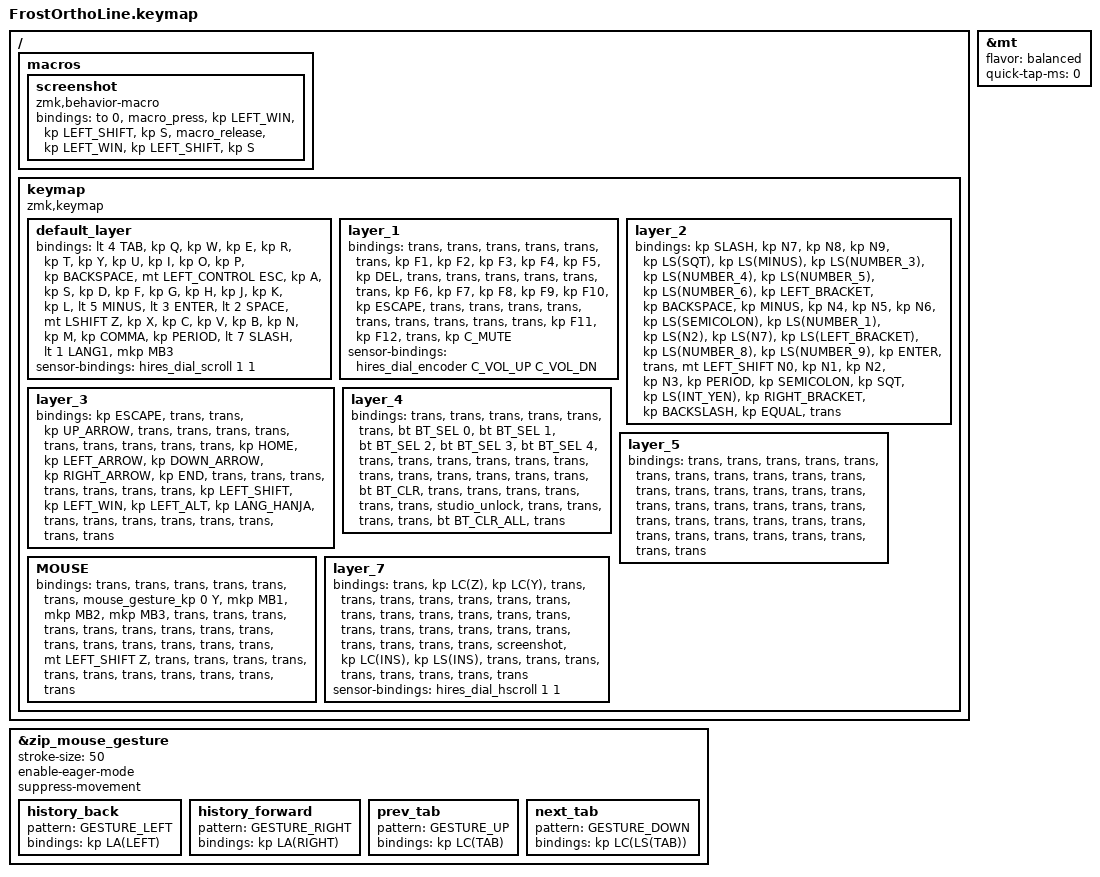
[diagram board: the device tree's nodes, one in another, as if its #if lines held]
#include <input/processors.dtsi>
#include <behaviors.dtsi>
#include <dt-bindings/zmk/bt.h>
#include <dt-bindings/zmk/keys.h>
#include <dt-bindings/zmk/pointing.h>
#include <mouse-gesture.dtsi>

#define MOUSE 6

&mt {
    flavor = "balanced";
    quick-tap-ms = <0>;
};

// マウスジェスチャー（AMLのYキーを長押ししながらセンサー1を動かす）
&zip_mouse_gesture {
    stroke-size = <50>; // 1ストロークと判定する移動量
    enable-eager-mode;
    suppress-movement; // ジェスチャー中はカーソルを動かさない

    history_back {
        pattern = <GESTURE_LEFT>;
        bindings = <&kp LA(LEFT)>; // 戻る
    };
    history_forward {
        pattern = <GESTURE_RIGHT>;
        bindings = <&kp LA(RIGHT)>; // 進む
    };
    prev_tab {
        pattern = <GESTURE_UP>;
        bindings = <&kp LC(TAB)>; // 次のタブ
    };
    next_tab {
        pattern = <GESTURE_DOWN>;
        bindings = <&kp LC(LS(TAB))>; // 前のタブ
    };
};

/ {
    // コンボは DYA Studio（zmk-feature-runtime-combo）から追加・編集する

    macros {
        screenshot: screenshot {
            compatible = "zmk,behavior-macro";
            #binding-cells = <0>;
            bindings =
                <&to 0>,
                <&macro_press>,
                <&kp LEFT_WIN &kp LEFT_SHIFT &kp S>,
                <&macro_release>,
                <&kp LEFT_WIN &kp LEFT_SHIFT &kp S>;
        };
    };

    keymap {
        compatible = "zmk,keymap";

        default_layer {
            bindings = <
&lt 4 TAB              &kp Q          &kp W  &kp E  &kp R  &kp T      &kp Y  &kp U  &kp I      &kp O       &kp P         &kp BACKSPACE
&mt LEFT_CONTROL ESC   &kp A          &kp S  &kp D  &kp F  &kp G      &kp H  &kp J  &kp K      &kp L       &lt 5 MINUS   &lt 3 ENTER
&lt 2 SPACE            &mt LSHIFT Z   &kp X  &kp C  &kp V  &kp B      &kp N  &kp M  &kp COMMA  &kp PERIOD  &lt 7 SLASH   &lt 1 LANG1
// ダイヤルのプッシュスイッチ: 中クリック
&mkp MB3
            >;

#ifdef FROSTORTHOLINE_HIRES_DIAL
            // ダイヤル: 縦スクロール（<入力カウント 出力値>、1 1 = 1カウントでホイール値1）
            // sensor-bindings がないレイヤーでは下のレイヤーの割り当てが使われる
            sensor-bindings = <&hires_dial_scroll 1 1>;
#endif
        };

        layer_1 {
            bindings = <
&trans  &trans  &trans  &trans  &trans  &trans      &kp F1  &kp F2  &kp F3  &kp F4   &kp F5   &kp DEL
&trans  &trans  &trans  &trans  &trans  &trans      &kp F6  &kp F7  &kp F8  &kp F9   &kp F10  &kp ESCAPE
&trans  &trans  &trans  &trans  &trans  &trans      &trans  &trans  &trans  &kp F11  &kp F12  &trans
// ダイヤルのプッシュスイッチ: ミュート
&kp C_MUTE
            >;

#ifdef FROSTORTHOLINE_HIRES_DIAL
            // ダイヤル: 音量（1回転あたり triggers-per-rotation 回キーを送る）
            sensor-bindings = <&hires_dial_encoder C_VOL_UP C_VOL_DN>;
#endif
        };

        layer_2 {
            bindings = <
&kp SLASH  &kp N7             &kp N8  &kp N9  &kp LS(SQT)        &kp LS(MINUS)     &kp LS(NUMBER_3)  &kp LS(NUMBER_4)  &kp LS(NUMBER_5)      &kp LS(NUMBER_6)   &kp LEFT_BRACKET  &kp BACKSPACE
&kp MINUS  &kp N4             &kp N5  &kp N6  &kp LS(SEMICOLON)  &kp LS(NUMBER_1)  &kp LS(N2)        &kp LS(N7)        &kp LS(LEFT_BRACKET)  &kp LS(NUMBER_8)   &kp LS(NUMBER_9)  &kp ENTER
&trans     &mt LEFT_SHIFT N0  &kp N1  &kp N2  &kp N3             &kp PERIOD        &kp SEMICOLON     &kp SQT           &kp LS(INT_YEN)       &kp RIGHT_BRACKET  &kp BACKSLASH     &kp EQUAL
&trans
            >;
        };

        layer_3 {
            bindings = <
&kp ESCAPE  &trans          &trans          &kp UP_ARROW    &trans           &trans        &trans  &trans  &trans  &trans  &trans  &trans
&trans      &kp HOME        &kp LEFT_ARROW  &kp DOWN_ARROW  &kp RIGHT_ARROW  &kp END       &trans  &trans  &trans  &trans  &trans  &trans
&trans      &kp LEFT_SHIFT  &kp LEFT_WIN    &kp LEFT_ALT    &kp LANG_HANJA   &trans        &trans  &trans  &trans  &trans  &trans  &trans
&trans
            >;
        };

        layer_4 {
            bindings = <
&trans  &trans  &trans  &trans  &trans  &trans      &bt BT_SEL 0    &bt BT_SEL 1  &bt BT_SEL 2  &bt BT_SEL 3  &bt BT_SEL 4  &trans
&trans  &trans  &trans  &trans  &trans  &trans      &trans          &trans        &trans        &trans        &trans        &bt BT_CLR
&trans  &trans  &trans  &trans  &trans  &trans      &studio_unlock  &trans        &trans        &trans        &trans        &bt BT_CLR_ALL
&trans
            >;
        };

        // センサー1 を縦スクロールに切り替え
        layer_5 {
            bindings = <
&trans  &trans  &trans  &trans  &trans  &trans      &trans  &trans  &trans  &trans  &trans  &trans
&trans  &trans  &trans  &trans  &trans  &trans      &trans  &trans  &trans  &trans  &trans  &trans
&trans  &trans  &trans  &trans  &trans  &trans      &trans  &trans  &trans  &trans  &trans  &trans
&trans
            >;
        };

        // AML: &trans 以外のキーは押しても AML から離脱しない
        MOUSE {
            bindings = <
&trans  &trans            &trans  &trans  &trans  &trans      &mouse_gesture_kp 0 Y  &mkp MB1  &mkp MB2  &mkp MB3  &trans  &trans
&trans  &trans            &trans  &trans  &trans  &trans      &trans                 &trans    &trans    &trans    &trans  &trans
&trans  &mt LEFT_SHIFT Z  &trans  &trans  &trans  &trans      &trans                 &trans    &trans    &trans    &trans  &trans
&trans
            >;
        };

        // センサー1 を横スクロールに切り替え + 編集系
        layer_7 {
            bindings = <
&trans  &kp LC(Z)  &kp LC(Y)    &trans       &trans       &trans      &trans  &trans  &trans  &trans  &trans  &trans
&trans  &trans     &trans       &trans       &trans       &trans      &trans  &trans  &trans  &trans  &trans  &trans
&trans  &trans     &screenshot  &kp LC(INS)  &kp LS(INS)  &trans      &trans  &trans  &trans  &trans  &trans  &trans
&trans
            >;

#ifdef FROSTORTHOLINE_HIRES_DIAL
            // ダイヤル: 横スクロール
            sensor-bindings = <&hires_dial_hscroll 1 1>;
#endif
        };
    };
};
